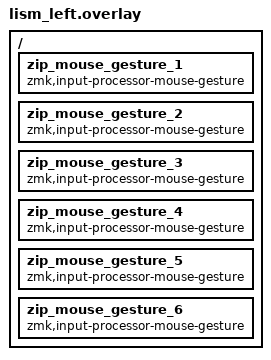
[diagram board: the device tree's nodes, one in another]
#include "lism.dtsi"

/ {
    zip_mouse_gesture_1: zip_mouse_gesture_1 {
        compatible = "zmk,input-processor-mouse-gesture";
    };
    zip_mouse_gesture_2: zip_mouse_gesture_2 {
        compatible = "zmk,input-processor-mouse-gesture";
    };
    zip_mouse_gesture_3: zip_mouse_gesture_3 {
        compatible = "zmk,input-processor-mouse-gesture";
    };
    zip_mouse_gesture_4: zip_mouse_gesture_4 {
        compatible = "zmk,input-processor-mouse-gesture";
    };
    zip_mouse_gesture_5: zip_mouse_gesture_5 {
        compatible = "zmk,input-processor-mouse-gesture";
    };
    zip_mouse_gesture_6: zip_mouse_gesture_6 {
        compatible = "zmk,input-processor-mouse-gesture";
    };
};
